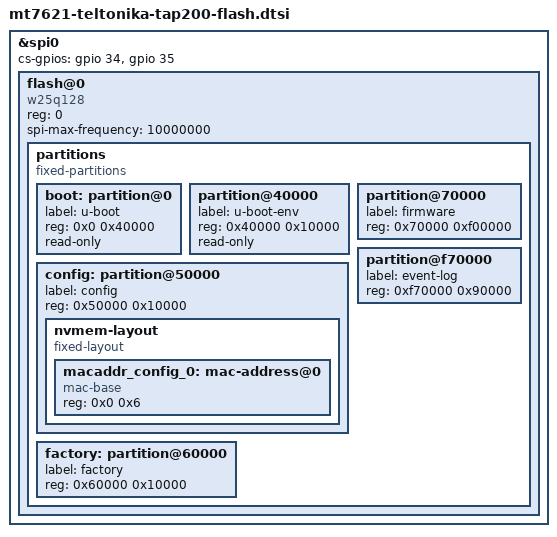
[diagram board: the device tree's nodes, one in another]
&spi0 {
	status = "okay";
	cs-gpios = <&gpio 34 GPIO_ACTIVE_HIGH>, <&gpio 35 GPIO_ACTIVE_HIGH>;

	flash@0 {
		compatible = "w25q128","jedec,spi-nor";
		reg = <0>;
		spi-max-frequency = <10000000>;

		partitions {
			compatible = "fixed-partitions";
			#address-cells = <1>;
			#size-cells = <1>;

			boot: partition@0 {
				label = "u-boot";
				reg = <0x0 0x40000>;
				read-only;
			};

			partition@40000 {
				label = "u-boot-env";
				reg = <0x40000 0x10000>;
				read-only;
			};

			config: partition@50000 {
				label = "config";
				reg = <0x50000 0x10000>;

				nvmem-layout {
					compatible = "fixed-layout";
					#address-cells = <1>;
					#size-cells = <1>;

					macaddr_config_0: mac-address@0 {
						compatible = "mac-base";
						reg = <0x0 0x6>;
						#nvmem-cell-cells = <1>;
					};
				};
			};

			factory: partition@60000 {
				label = "factory";
				reg = <0x60000 0x10000>;
			};

			partition@70000 {
				label = "firmware";
				reg = <0x70000 0xf00000>;
			};

			partition@f70000 {
				label = "event-log";
				reg = <0xf70000 0x90000>;
			};
		};
	};
};
